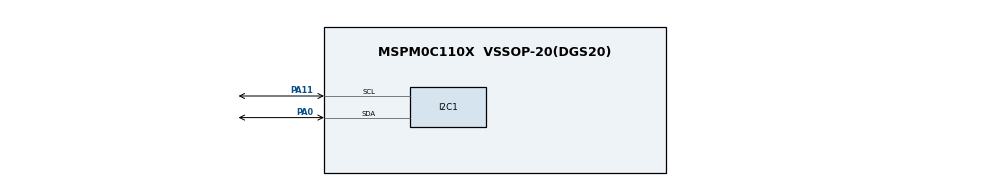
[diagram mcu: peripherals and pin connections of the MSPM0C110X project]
// @cliArgs --device "MSPM0C110X" --package "VSSOP-20(DGS20)" --part "Default"
// @cliArgs --board /ti/boards/LP_MSPM0C1104 --rtos nortos

/**
 * Import the modules used in this configuration.
 */
const Board  = scripting.addModule("/ti/driverlib/Board");
const GPIO   = scripting.addModule("/ti/driverlib/GPIO", {}, false);
const GPIO1  = GPIO.addInstance();
const I2C    = scripting.addModule("/ti/driverlib/I2C", {}, false);
const I2C1   = I2C.addInstance();
const SYSCTL = scripting.addModule("/ti/driverlib/SYSCTL");

/**
 * Write custom configuration values to the imported modules.
 */
Board.configureUnused = true;

GPIO1.$name                          = "GPIO_LEDS";
GPIO1.associatedPins.create(2);
GPIO1.associatedPins[0].$name        = "USER_LED_1";
GPIO1.associatedPins[0].initialValue = "SET";
GPIO1.associatedPins[0].assignedPin  = "22";
GPIO1.associatedPins[1].$name        = "USER_TEST";
GPIO1.associatedPins[1].assignedPin  = "2";
GPIO1.associatedPins[1].initialValue = "SET";

I2C1.$name                             = "I2C";
I2C1.basicControllerBusSpeed           = 400000;
I2C1.advControllerTXFIFOTRIG           = "BYTES_1";
I2C1.advTargetTXFIFOTRIG               = "BYTES_1";
I2C1.basicTargetAddress                = 0x48;
I2C1.basicEnableTarget                 = true;
I2C1.intTarget                         = ["RXFIFO_TRIGGER","START","STOP"];
I2C1.advAnalogGlitchFilter             = "DISABLED";
I2C1.advTargetTXEmptyEn                = true;
I2C1.peripheral.$assign                = "I2C0";
I2C1.peripheral.sdaPin.$assign         = "PA0";
I2C1.peripheral.sclPin.$assign         = "PA11";

SYSCTL.powerPolicy = "STOP0";
SYSCTL.clockTreeEn = true;
